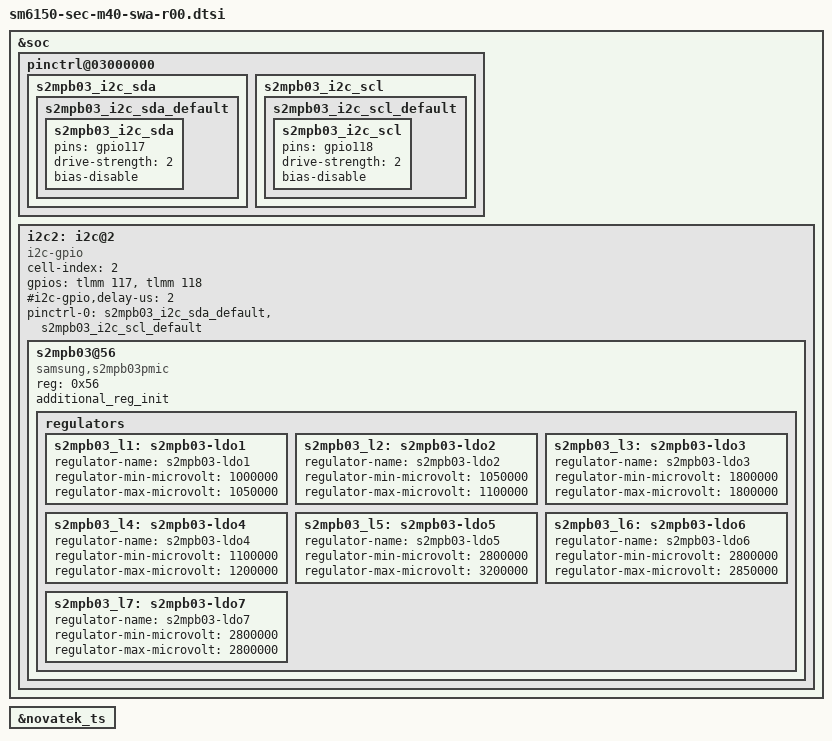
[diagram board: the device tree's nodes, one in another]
/* Copyright (c) 2018, The Linux Foundation. All rights reserved.
 *
 * This program is free software; you can redistribute it and/or modify
 * it under the terms of the GNU General Public License version 2 and
 * only version 2 as published by the Free Software Foundation.
 *
 * This program is distributed in the hope that it will be useful,
 * but WITHOUT ANY WARRANTY; without even the implied warranty of
 * MERCHANTABILITY or FITNESS FOR A PARTICULAR PURPOSE.  See the
 * GNU General Public License for more details.
 */

#include "sm6150-sec-m40-common.dtsi"
#include "sm6150-sec-m40-input-common.dtsi"

&soc {
	pinctrl@03000000 {
		s2mpb03_i2c_sda {
			s2mpb03_i2c_sda_default: s2mpb03_i2c_sda_default {
				s2mpb03_i2c_sda {
					pins = "gpio117";
					drive-strength = <2>;
					bias-disable;
				};
			};
		};
		s2mpb03_i2c_scl {
			s2mpb03_i2c_scl_default: s2mpb03_i2c_scl_default {
				s2mpb03_i2c_scl {
					pins = "gpio118";
					drive-strength = <2>;
					bias-disable;
				};
			};
		};
	};

	/* S2MPB03 Camera PMIC */
	i2c2: i2c@2 {
		cell-index = <2>;
		compatible = "i2c-gpio";
		gpios = <&tlmm 117 0 /* sda */
			&tlmm 118 0 /* scl */
		>;
		#i2c-gpio,delay-us = <2>;
		#address-cells = <1>;
		#size-cells = <0>;

		pinctrl-names = "default";
		pinctrl-0 = <&s2mpb03_i2c_sda_default &s2mpb03_i2c_scl_default>;

		/* S2MPB03 Camera PMIC */
		s2mpb03@56 {
			compatible = "samsung,s2mpb03pmic";
			reg = <0x56>;
			additional_reg_init;

			regulators {
				s2mpb03_l1: s2mpb03-ldo1 {
					regulator-name = "s2mpb03-ldo1";
					regulator-min-microvolt = <1000000>;
					regulator-max-microvolt = <1050000>;
				};

				s2mpb03_l2: s2mpb03-ldo2 {
					regulator-name = "s2mpb03-ldo2";
					regulator-min-microvolt = <1050000>;
					regulator-max-microvolt = <1100000>;
				};

				s2mpb03_l3: s2mpb03-ldo3 {
					regulator-name = "s2mpb03-ldo3";
					regulator-min-microvolt = <1800000>;
					regulator-max-microvolt = <1800000>;
				};

				s2mpb03_l4: s2mpb03-ldo4 {
					regulator-name = "s2mpb03-ldo4";
					regulator-min-microvolt = <1100000>;
					regulator-max-microvolt = <1200000>;
				};

				s2mpb03_l5: s2mpb03-ldo5 {
					regulator-name = "s2mpb03-ldo5";
					regulator-min-microvolt = <2800000>;
					regulator-max-microvolt = <3200000>;
				};

				s2mpb03_l6: s2mpb03-ldo6 {
					regulator-name = "s2mpb03-ldo6";
					regulator-min-microvolt = <2800000>;
					regulator-max-microvolt = <2850000>;
				};

				s2mpb03_l7: s2mpb03-ldo7 {
					regulator-name = "s2mpb03-ldo7";
					regulator-min-microvolt = <2800000>;
					regulator-max-microvolt = <2800000>;
				};
			};
		};
	};
};

&novatek_ts {
	status = "okay";
};
